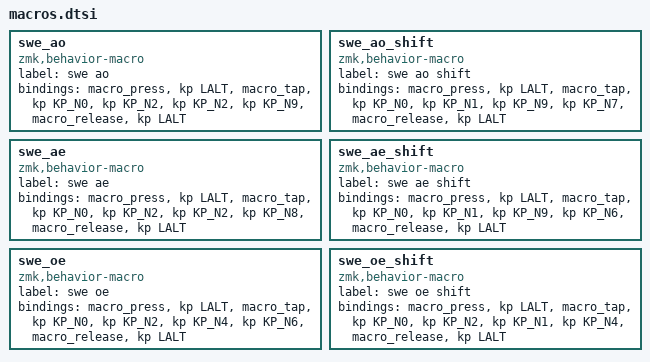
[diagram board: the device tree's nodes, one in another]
swe_ao: swe_ao {
        compatible = "zmk,behavior-macro";
        label = "swe ao";
        #binding-cells = <0>;
        bindings
          = <&macro_press   &kp LALT>
          , <&macro_tap     &kp KP_N0 &kp KP_N2 &kp KP_N2 &kp KP_N9>
          , <&macro_release &kp LALT>;
};
swe_ao_shift: swe_ao_shift {
        compatible = "zmk,behavior-macro";
        label = "swe ao shift";
        #binding-cells = <0>;
        bindings
          = <&macro_press   &kp LALT>
          , <&macro_tap     &kp KP_N0 &kp KP_N1 &kp KP_N9 &kp KP_N7>
          , <&macro_release &kp LALT>;
};

swe_ae: swe_ae {
        compatible = "zmk,behavior-macro";
        label = "swe ae";
        #binding-cells = <0>;
        bindings
          = <&macro_press   &kp LALT>
          , <&macro_tap     &kp KP_N0 &kp KP_N2 &kp KP_N2 &kp KP_N8>
          , <&macro_release &kp LALT>;
};
swe_ae_shift: swe_ae_shift {
        compatible = "zmk,behavior-macro";
        label = "swe ae shift";
        #binding-cells = <0>;
        bindings
          = <&macro_press   &kp LALT>
          , <&macro_tap     &kp KP_N0 &kp KP_N1 &kp KP_N9 &kp KP_N6>
          , <&macro_release &kp LALT>;
};

swe_oe: swe_oe {
        compatible = "zmk,behavior-macro";
        label = "swe oe";
        #binding-cells = <0>;
        bindings
          = <&macro_press   &kp LALT>
          , <&macro_tap     &kp KP_N0 &kp KP_N2 &kp KP_N4 &kp KP_N6>
          , <&macro_release &kp LALT>;
};
swe_oe_shift: swe_oe_shift {
        compatible = "zmk,behavior-macro";
        label = "swe oe shift";
        #binding-cells = <0>;
        bindings
          = <&macro_press   &kp LALT>
          , <&macro_tap     &kp KP_N0 &kp KP_N2 &kp KP_N1 &kp KP_N4>
          , <&macro_release &kp LALT>;
};
